AUTOSAR XML (schema 00049)
# Copyright (c) 2018 Vector Informatik GmbH.
standard types defined: boolean, uint16, uint32, uint8
package /VehicleProject
  system System
package /Diagnostics
  diagnostic contribution set DiagnosticContributionSet: ecu-instance=[MyECU, OtherECU, Tester], service-tables=[DS_MyECU, DS_OtherECU, DS_Tester]
  diagnostic service table DS_MyECU: diagnostic-connections=[DC_0xE001_oMyECU_oCAN, DC_0xE002_oMyECU_oCAN, DC_0xE004_oMyECU_oCAN], ecu-instance=MyECU
  diagnostic service table DS_OtherECU: diagnostic-connections=DC_0xE003_oOtherECU_oCAN, ecu-instance=OtherECU
  diagnostic service table DS_Tester: diagnostic-connections=[DC_0xE001_oMyECU_oCAN, DC_0xE002_oMyECU_oCAN, DC_0xE003_oOtherECU_oCAN, DC_0xE004_oMyECU_oCAN], ecu-instance=Tester
  4 x diagnostic connection, all with functional-request=msg_diag_RequestGlobal_oTN_0x00E0_Tester:
    DC_0xE001_oMyECU_oCAN: periodic-response-uudt=PT_msg_diag_Uudt_Response_MyECU, physical-request=msg_diag_Request_MyECU_oTN_0x0001_MyECU, response=msg_diag_Response_MyECU_oTN_0x0001_MyECU
    DC_0xE002_oMyECU_oCAN: physical-request=msg_diag_Request_MyECU_Slave3_oTN_0x0002_MyECU, response=msg_diag_Response_MyECU_Slave3_oTN_0x0002_MyECU
    DC_0xE003_oOtherECU_oCAN: periodic-response-uudt=PT_msg_diag_Uudt_Response_OtherECU, physical-request=msg_diag_Request_OtherECU_oTN_0x0003_OtherECU, response=msg_diag_Response_OtherECU_oTN_0x0003_OtherECU
    DC_0xE004_oMyECU_oCAN: physical-request=msg_diag_Request_MyECU_Slave1_oTN_0x0004_MyECU, response=msg_diag_Response_MyECU_Slave1_oTN_0x0004_MyECU
package /NM
  nm config NmConfig: can-nm-cluster-coupling=coupled-cluster=CAN
    can nm cluster CAN: communication-cluster=CAN, nm-channel-id=0, nm-cbv-position=0, nm-msg-cycle-time=0.1, nm-network-timeout=1, nm-nid-position=1, nm-repeat-message-time=0.4, nm-wait-bus-sleep-time=0.75
      can nm node MyECU: controller=MyECU/CT_CAN, nm-if-ecu=MyECU_CAN, nm-node-id=0, rx-nm-pdu=[msg_nm_OtherECU_oCAN, msg_nm_RearECU_oCAN], tx-nm-pdu=msg_nm_MyECU_oCAN, nm-msg-cycle-offset=0, nm-msg-reduced-time=0.05, nm-range-config={lower-can-id=1024, upper-can-id=1087}
      can nm node OtherECU: controller=OtherECU/CT_CAN, nm-if-ecu=OtherECU_CAN, nm-node-id=0, rx-nm-pdu=[msg_nm_MyECU_oCAN, msg_nm_RearECU_oCAN], tx-nm-pdu=msg_nm_OtherECU_oCAN, nm-msg-cycle-offset=0, nm-msg-reduced-time=0.05, nm-range-config={lower-can-id=1024, upper-can-id=1087}
      can nm node RearECU: controller=RearECU/CT_CAN, nm-if-ecu=RearECU_CAN, nm-node-id=1, rx-nm-pdu=[msg_nm_MyECU_oCAN, msg_nm_OtherECU_oCAN], tx-nm-pdu=msg_nm_RearECU_oCAN, nm-msg-cycle-offset=0, nm-msg-reduced-time=0.05, nm-range-config={lower-can-id=1024, upper-can-id=1087}
    nm-if-ecus:
      nm ecu MyECU_CAN: ecu-instance=MyECU, nm-node-id-enabled=true, nm-user-data-enabled=true
      nm ecu OtherECU_CAN: ecu-instance=OtherECU, nm-node-id-enabled=true, nm-user-data-enabled=true
      nm ecu RearECU_CAN: ecu-instance=RearECU, nm-node-id-enabled=true, nm-user-data-enabled=true
package /TP
  can tp config CAN: communication-cluster=CAN
    6 x can tp address:
      TA_0x0000: tp-address=0
      TA_0x0001: tp-address=1
      TA_0x0002: tp-address=2
      TA_0x0003: tp-address=3
      TA_0x0004: tp-address=4
      TA_0x00E0: tp-address=224
    can tp channel TPCH: channel-id=0, channel-mode=FULL-DUPLEX-MODE
    can-tp-connection addressing-format=STANDARD, can-tp-channel=TPCH, data-pdu=msg_diag_RequestGlobal_Tp_oCAN, multicast=TA_0x0000, receiver=[TN_MyECU, TN_OtherECU], ta-type=FUNCTIONAL, tp-sdu=msg_diag_RequestGlobal_oCAN, transmitter=TN_0x00E0_Tester:
      ident msg_diag_RequestGlobal_oTN_0x00E0_Tester
    can-tp-connection addressing-format=STANDARD, can-tp-channel=TPCH, data-pdu=msg_diag_Request_MyECU_Tp_oCAN, flow-control-pdu=msg_diag_Response_MyECU_Tp_oCAN, receiver=TN_0x0001_MyECU, ta-type=PHYSICAL, tp-sdu=msg_diag_Request_MyECU_oCAN, transmitter=TN_0x00E0_Tester:
      ident msg_diag_Request_MyECU_oTN_0x0001_MyECU
    can-tp-connection addressing-format=STANDARD, can-tp-channel=TPCH, data-pdu=msg_diag_Request_MyECU_Slave1_Tp_oCAN, flow-control-pdu=msg_diag_Response_MyECU_Slave1_Tp_oCAN, receiver=TN_0x0004_MyECU, ta-type=PHYSICAL, tp-sdu=msg_diag_Request_MyECU_Slave1_oCAN, transmitter=TN_0x00E0_Tester:
      ident msg_diag_Request_MyECU_Slave1_oTN_0x0004_MyECU
    can-tp-connection addressing-format=STANDARD, can-tp-channel=TPCH, data-pdu=msg_diag_Request_MyECU_Slave3_Tp_oCAN, flow-control-pdu=msg_diag_Response_MyECU_Slave3_Tp_oCAN, receiver=TN_0x0002_MyECU, ta-type=PHYSICAL, tp-sdu=msg_diag_Request_MyECU_Slave3_oCAN, transmitter=TN_0x00E0_Tester:
      ident msg_diag_Request_MyECU_Slave3_oTN_0x0002_MyECU
    can-tp-connection addressing-format=STANDARD, can-tp-channel=TPCH, data-pdu=msg_diag_Request_OtherECU_Tp_oCAN, flow-control-pdu=msg_diag_Response_OtherECU_Tp_oCAN, receiver=TN_0x0003_OtherECU, ta-type=PHYSICAL, tp-sdu=msg_diag_Request_OtherECU_oCAN, transmitter=TN_0x00E0_Tester:
      ident msg_diag_Request_OtherECU_oTN_0x0003_OtherECU
    can-tp-connection addressing-format=STANDARD, can-tp-channel=TPCH, data-pdu=msg_diag_Response_MyECU_Tp_oCAN, flow-control-pdu=msg_diag_Request_MyECU_Tp_oCAN, receiver=TN_0x00E0_Tester, ta-type=PHYSICAL, tp-sdu=msg_diag_Response_MyECU_oCAN, transmitter=TN_0x0001_MyECU:
      ident msg_diag_Response_MyECU_oTN_0x0001_MyECU
    can-tp-connection addressing-format=STANDARD, can-tp-channel=TPCH, data-pdu=msg_diag_Response_MyECU_Slave1_Tp_oCAN, flow-control-pdu=msg_diag_Request_MyECU_Slave1_Tp_oCAN, receiver=TN_0x00E0_Tester, ta-type=PHYSICAL, tp-sdu=msg_diag_Response_MyECU_Slave1_oCAN, transmitter=TN_0x0004_MyECU:
      ident msg_diag_Response_MyECU_Slave1_oTN_0x0004_MyECU
    can-tp-connection addressing-format=STANDARD, can-tp-channel=TPCH, data-pdu=msg_diag_Response_MyECU_Slave3_Tp_oCAN, flow-control-pdu=msg_diag_Request_MyECU_Slave3_Tp_oCAN, receiver=TN_0x00E0_Tester, ta-type=PHYSICAL, tp-sdu=msg_diag_Response_MyECU_Slave3_oCAN, transmitter=TN_0x0002_MyECU:
      ident msg_diag_Response_MyECU_Slave3_oTN_0x0002_MyECU
    can-tp-connection addressing-format=STANDARD, can-tp-channel=TPCH, data-pdu=msg_diag_Response_OtherECU_Tp_oCAN, flow-control-pdu=msg_diag_Request_OtherECU_Tp_oCAN, receiver=TN_0x00E0_Tester, ta-type=PHYSICAL, tp-sdu=msg_diag_Response_OtherECU_oCAN, transmitter=TN_0x0003_OtherECU:
      ident msg_diag_Response_OtherECU_oTN_0x0003_OtherECU
    tp-ecus:
      cycle-time-main-function=0.005, ecu-instance=MyECU
      cycle-time-main-function=0.005, ecu-instance=OtherECU
      cycle-time-main-function=0.005, ecu-instance=Tester
    7 x can tp node:
      TN_0x0001_MyECU: connector=MyECU/CN_CAN, tp-address=TA_0x0001
      TN_0x0002_MyECU: connector=MyECU/CN_CAN, tp-address=TA_0x0002
      TN_0x0003_OtherECU: connector=OtherECU/CN_CAN, tp-address=TA_0x0003
      TN_0x0004_MyECU: connector=MyECU/CN_CAN, tp-address=TA_0x0004
      TN_0x00E0_Tester: connector=Tester/CN_CAN, tp-address=TA_0x00E0
      TN_MyECU: connector=MyECU/CN_CAN
      TN_OtherECU: connector=OtherECU/CN_CAN
package /Cluster
  can cluster CAN: baudrate=500000, protocol-name=CAN, can-fd-baudrate=500000  # CAN_SecOC_FD_Mode2
    can physical channel CHNL: comm-connectors=[MyECU/CN_CAN, OtherECU/CN_CAN, RearECU/CN_CAN, Tester/CN_CAN]
      frame GlobalTimeMaster_oCAN: id 0x380, from RearECU, to MyECU OtherECU, frame-length=8, can-addressing-mode=STANDARD, can-frame-rx-behavior=ANY, can-frame-tx-behavior=CAN-20
        user defined pdu GlobalTimeMaster_oCAN: length=8
      frame msg_diag_Request_MyECU_oCAN: id 0x610, from Tester, to MyECU, frame-length=8, can-addressing-mode=STANDARD, can-frame-rx-behavior=CAN-20, can-frame-tx-behavior=CAN-20
        n pdu msg_diag_Request_MyECU_Tp_oCAN: length=8
      frame msg_diag_Request_MyECU_Slave1_oCAN: id 0x615, from Tester, to MyECU, frame-length=8, can-addressing-mode=STANDARD, can-frame-rx-behavior=CAN-20, can-frame-tx-behavior=CAN-20
        n pdu msg_diag_Request_MyECU_Slave1_Tp_oCAN: length=8
      frame msg_diag_Request_MyECU_Slave3_oCAN: id 0x611, from Tester, to MyECU, frame-length=8, can-addressing-mode=STANDARD, can-frame-rx-behavior=CAN-20, can-frame-tx-behavior=CAN-20
        n pdu msg_diag_Request_MyECU_Slave3_Tp_oCAN: length=8
      frame msg_diag_Request_OtherECU_oCAN: id 0x620, from Tester, to OtherECU, frame-length=8, can-addressing-mode=STANDARD, can-frame-rx-behavior=CAN-20, can-frame-tx-behavior=CAN-20
        n pdu msg_diag_Request_OtherECU_Tp_oCAN: length=8
      frame msg_diag_RequestGlobal_oCAN: id 0x614, from Tester, to MyECU OtherECU, frame-length=8, can-addressing-mode=STANDARD, can-frame-rx-behavior=CAN-20, can-frame-tx-behavior=CAN-20
        n pdu msg_diag_RequestGlobal_Tp_oCAN: length=8
      frame msg_diag_Response_MyECU_oCAN: id 0x612, from MyECU, to Tester, frame-length=8, can-addressing-mode=STANDARD, can-frame-rx-behavior=CAN-20, can-frame-tx-behavior=CAN-20
        n pdu msg_diag_Response_MyECU_Tp_oCAN: length=8
      frame msg_diag_Response_MyECU_Slave1_oCAN: id 0x618, from MyECU, to Tester, frame-length=8, can-addressing-mode=STANDARD, can-frame-rx-behavior=CAN-20, can-frame-tx-behavior=CAN-20
        n pdu msg_diag_Response_MyECU_Slave1_Tp_oCAN: length=8
      frame msg_diag_Response_MyECU_Slave3_oCAN: id 0x613, from MyECU, to Tester, frame-length=8, can-addressing-mode=STANDARD, can-frame-rx-behavior=CAN-20, can-frame-tx-behavior=CAN-20
        n pdu msg_diag_Response_MyECU_Slave3_Tp_oCAN: length=8
      frame msg_diag_Response_OtherECU_oCAN: id 0x622, from OtherECU, to Tester, frame-length=8, can-addressing-mode=STANDARD, can-frame-rx-behavior=CAN-20, can-frame-tx-behavior=CAN-20
        n pdu msg_diag_Response_OtherECU_Tp_oCAN: length=8
      frame msg_diag_Uudt_Response_MyECU_oCAN: id 0x616, from MyECU, to Tester, frame-length=8, can-addressing-mode=STANDARD, can-frame-rx-behavior=CAN-20, can-frame-tx-behavior=CAN-20
        dcm i pdu msg_diag_Uudt_Response_MyECU_oCAN: length=8, diag-pdu-type=DIAG-RESPONSE
      frame msg_diag_Uudt_Response_OtherECU_oCAN: id 0x626, from OtherECU, to Tester, frame-length=8, can-addressing-mode=STANDARD, can-frame-rx-behavior=CAN-20, can-frame-tx-behavior=CAN-20
        dcm i pdu msg_diag_Uudt_Response_OtherECU_oCAN: length=8, diag-pdu-type=DIAG-RESPONSE
      frame msg_nm_MyECU_oCAN: id 0x400, from MyECU, to OtherECU RearECU, frame-length=8, can-addressing-mode=STANDARD, can-frame-rx-behavior=ANY, can-frame-tx-behavior=CAN-20
        nm pdu msg_nm_MyECU_oCAN: length=8, unused-bit-pattern=0
          signal NmUd_MyECU_16bit_omsg_nm_MyECU_oCAN: start 16, 16 bit, little-endian, i-signal-type=PRIMITIVE, init-value=0, base-type=uint16, compu {identical}, range raw 0..65535, transfer-property=PENDING
          signal NmUd_MyECU_32bit_omsg_nm_MyECU_oCAN: start 32, 32 bit, little-endian, i-signal-type=PRIMITIVE, init-value=0, base-type=uint32, compu {identical}, range raw 0..4294967295, transfer-property=PENDING
      frame msg_nm_OtherECU_oCAN: id 0x402, from OtherECU, to MyECU RearECU, frame-length=8, can-addressing-mode=STANDARD, can-frame-rx-behavior=ANY, can-frame-tx-behavior=CAN-20
        nm pdu msg_nm_OtherECU_oCAN: length=8, unused-bit-pattern=0
          signal NmUd_OtherECU_16bit_omsg_nm_OtherECU_oCAN: start 16, 16 bit, little-endian, i-signal-type=PRIMITIVE, init-value=0, base-type=uint16, compu {identical}, range raw 0..65535, transfer-property=PENDING
          signal NmUd_OtherECU_32bit_omsg_nm_OtherECU_oCAN: start 32, 32 bit, little-endian, i-signal-type=PRIMITIVE, init-value=0, base-type=uint32, compu {identical}, range raw 0..4294967295, transfer-property=PENDING
      frame msg_nm_RearECU_oCAN: id 0x401, from RearECU, to MyECU OtherECU, frame-length=8, can-addressing-mode=STANDARD, can-frame-rx-behavior=ANY, can-frame-tx-behavior=CAN-20
        nm pdu msg_nm_RearECU_oCAN: length=8, unused-bit-pattern=0
          signal NmUd_RearECU_16bit_omsg_nm_RearECU_oCAN: start 16, 16 bit, little-endian, i-signal-type=PRIMITIVE, init-value=0, base-type=uint16, compu {identical}, range raw 0..65535, transfer-property=PENDING
          signal NmUd_RearECU_32bit_omsg_nm_RearECU_oCAN: start 32, 32 bit, little-endian, i-signal-type=PRIMITIVE, init-value=0, base-type=uint32, compu {identical}, range raw 0..4294967295, transfer-property=PENDING
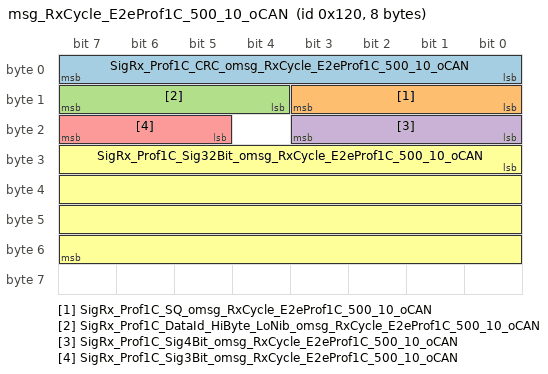
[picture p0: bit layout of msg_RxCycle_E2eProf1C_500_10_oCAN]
      frame msg_RxCycle_E2eProf1C_500_10_oCAN: id 0x120, from RearECU, to MyECU, frame-length=8, can-addressing-mode=STANDARD, can-frame-rx-behavior=ANY, can-frame-tx-behavior=CAN-FD
        pdu msg_RxCycle_E2eProf1C_500_10_oCAN: length=8, minimum-delay=0, transmission-mode-false-timing=cyclic-timing={time-offset=0.01, time-period=0.5}, transmission-mode-true-timing=cyclic-timing={time-offset=0.01, time-period=0.5}, unused-bit-pattern=0
          signal SigRx_Prof1C_CRC_omsg_RxCycle_E2eProf1C_500_10_oCAN: start 0, 8 bit, little-endian, i-signal-type=PRIMITIVE, init-value=0, base-type=uint8, compu {identical}, range raw 0..255, transfer-property=PENDING, to MyECU
          signal SigRx_Prof1C_SQ_omsg_RxCycle_E2eProf1C_500_10_oCAN: start 8, 4 bit, little-endian, i-signal-type=PRIMITIVE, init-value=0, base-type=uint8, compu {identical}, range raw 0..15, transfer-property=PENDING, to MyECU
          signal SigRx_Prof1C_DataId_HiByte_LoNib_omsg_RxCycle_E2eProf1C_500_10_oCAN: start 12, 4 bit, little-endian, i-signal-type=PRIMITIVE, init-value=0, base-type=uint8, compu {identical}, range raw 0..15, transfer-property=PENDING, to MyECU
          signal SigRx_Prof1C_Sig4Bit_omsg_RxCycle_E2eProf1C_500_10_oCAN: start 16, 4 bit, little-endian, i-signal-type=PRIMITIVE, init-value=0, base-type=uint8, compu {identical}, range raw 0..15, transfer-property=PENDING, to MyECU
          signal SigRx_Prof1C_Sig3Bit_omsg_RxCycle_E2eProf1C_500_10_oCAN: start 21, 3 bit, little-endian, i-signal-type=PRIMITIVE, init-value=0, base-type=uint8, compu {identical}, range raw 0..7, transfer-property=PENDING, to MyECU
          signal SigRx_Prof1C_Sig32Bit_omsg_RxCycle_E2eProf1C_500_10_oCAN: start 24, 32 bit, little-endian, i-signal-type=PRIMITIVE, init-value=0, base-type=uint32, compu {identical}, range raw 0..4294967295, transfer-property=PENDING, to MyECU
          mapping SG_RgRx_Prof1C_RxCycle: i-signal-group=SG_RgRx_Prof1C_RxCycle_omsg_RxCycle_E2eProf1C_500_10_oCAN, transfer-property=PENDING
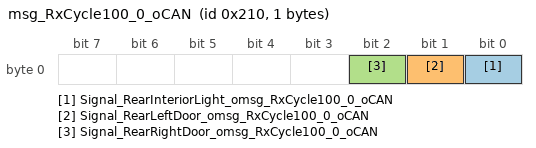
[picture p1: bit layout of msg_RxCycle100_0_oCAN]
      frame msg_RxCycle100_0_oCAN: id 0x210, from RearECU, to MyECU, frame-length=1, can-addressing-mode=STANDARD, can-frame-rx-behavior=ANY, can-frame-tx-behavior=CAN-FD
        pdu msg_RxCycle100_0_oCAN: length=1, minimum-delay=0, transmission-mode-false-timing=cyclic-timing={time-offset=0, time-period=0.1}, transmission-mode-true-timing=cyclic-timing={time-offset=0, time-period=0.1}, unused-bit-pattern=0
          signal Signal_RearInteriorLight_omsg_RxCycle100_0_oCAN: start 0, 1 bit, little-endian, i-signal-type=PRIMITIVE, init-value=0, base-type=boolean, compu {identical}, range raw 0..1, transfer-property=PENDING, to MyECU
          signal Signal_RearLeftDoor_omsg_RxCycle100_0_oCAN: start 1, 1 bit, little-endian, i-signal-type=PRIMITIVE, init-value=0, base-type=boolean, compu {identical}, range raw 0..1, transfer-property=PENDING, to MyECU
          signal Signal_RearRightDoor_omsg_RxCycle100_0_oCAN: start 2, 1 bit, little-endian, i-signal-type=PRIMITIVE, init-value=0, base-type=boolean, compu {identical}, range raw 0..1, transfer-property=PENDING, to MyECU
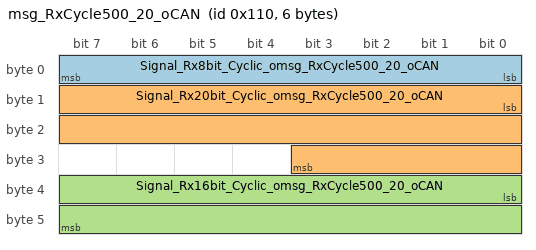
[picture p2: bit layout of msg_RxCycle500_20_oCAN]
      frame msg_RxCycle500_20_oCAN: id 0x110, from RearECU, to MyECU, frame-length=6, can-addressing-mode=STANDARD, can-frame-rx-behavior=ANY, can-frame-tx-behavior=CAN-FD
        pdu msg_RxCycle500_20_oCAN: length=6, minimum-delay=0, transmission-mode-false-timing=cyclic-timing={time-offset=0.02, time-period=0.5}, transmission-mode-true-timing=cyclic-timing={time-offset=0.02, time-period=0.5}, unused-bit-pattern=0
          signal Signal_Rx8bit_Cyclic_omsg_RxCycle500_20_oCAN: start 0, 8 bit, little-endian, i-signal-type=PRIMITIVE, init-value=15, base-type=uint8, compu {identical}, range raw 0..255, transfer-property=PENDING, to MyECU
          signal Signal_Rx20bit_Cyclic_omsg_RxCycle500_20_oCAN: start 8, 20 bit, little-endian, i-signal-type=PRIMITIVE, init-value=1, base-type=uint32, compu {identical}, range raw 0..1048575, transfer-property=PENDING, to MyECU
          signal Signal_Rx16bit_Cyclic_omsg_RxCycle500_20_oCAN: start 32, 16 bit, little-endian, i-signal-type=PRIMITIVE, init-value=32768, base-type=uint16, compu {identical}, range raw 0..65535, transfer-property=PENDING, to MyECU
      frame msg_RxEvent_20_oCAN: id 0x310, from RearECU, to MyECU, frame-length=4, can-addressing-mode=STANDARD, can-frame-rx-behavior=ANY, can-frame-tx-behavior=CAN-FD
        pdu msg_RxEvent_20_oCAN: length=4, minimum-delay=0, transmission-mode-false-timing=event-controlled-timing={number-of-repetitions=0, repetition-period=0}, transmission-mode-true-timing=event-controlled-timing={number-of-repetitions=0, repetition-period=0}, unused-bit-pattern=0
          signal Signal_Rx11bit_OnWrite_omsg_RxEvent_20_oCAN: start 0, 11 bit, little-endian, i-signal-type=PRIMITIVE, init-value=50, base-type=uint16, compu {identical}, range raw 0..2047, transfer-property=TRIGGERED-WITHOUT-REPETITION, to MyECU
          signal Signal_Rx15bit_OnWrite_omsg_RxEvent_20_oCAN: start 12, 15 bit, little-endian, i-signal-type=PRIMITIVE, init-value=25, base-type=uint16, compu {identical}, range raw 0..32767, transfer-property=TRIGGERED-WITHOUT-REPETITION, to MyECU
      frame msg_SecOC_MyECU_Rx_oCAN: id 0x528, from RearECU, to MyECU, frame-length=8, can-addressing-mode=STANDARD, can-frame-rx-behavior=ANY, can-frame-tx-behavior=CAN-20
        secured i pdu msg_SecOC_MyECU_Rx_Sc_oCAN: length=8, authentication-props=Authmsg_SecOC_MyECU_Rx_Sc_oCAN, freshness-props=Freshnessmsg_SecOC_MyECU_Rx_Sc_oCAN, payload=PT_msg_SecOC_MyECU_Rx, secure-communication-props={auth-info-tx-length=32, data-id=11, freshness-value-length=32, freshness-value-tx-length=16}
      frame msg_SecOC_MyECU_Tx_oCAN: id 0x520, from MyECU, to RearECU, frame-length=8, can-addressing-mode=STANDARD, can-frame-rx-behavior=ANY, can-frame-tx-behavior=CAN-20
        secured i pdu msg_SecOC_MyECU_Tx_Sc_oCAN: length=8, authentication-props=Authmsg_SecOC_MyECU_Tx_Sc_oCAN, freshness-props=Freshnessmsg_SecOC_MyECU_Tx_Sc_oCAN, payload=PT_msg_SecOC_MyECU_Tx, secure-communication-props={auth-info-tx-length=32, data-id=10, freshness-value-length=32, freshness-value-tx-length=16}
      frame msg_SecOC_OtherECU_Rx_oCAN: id 0x538, from RearECU, to OtherECU, frame-length=8, can-addressing-mode=STANDARD, can-frame-rx-behavior=ANY, can-frame-tx-behavior=CAN-20
        secured i pdu msg_SecOC_OtherECU_Rx_Sc_oCAN: length=8, authentication-props=Authmsg_SecOC_OtherECU_Rx_Sc_oCAN, freshness-props=Freshnessmsg_SecOC_OtherECU_Rx_Sc_oCAN, payload=PT_msg_SecOC_OtherECU_Rx, secure-communication-props={auth-info-tx-length=32, data-id=21, freshness-value-length=32, freshness-value-tx-length=16}
      frame msg_SecOC_OtherECU_Tx_oCAN: id 0x530, from OtherECU, to RearECU, frame-length=8, can-addressing-mode=STANDARD, can-frame-rx-behavior=ANY, can-frame-tx-behavior=CAN-20
        secured i pdu msg_SecOC_OtherECU_Tx_Sc_oCAN: length=8, authentication-props=Authmsg_SecOC_OtherECU_Tx_Sc_oCAN, freshness-props=Freshnessmsg_SecOC_OtherECU_Tx_Sc_oCAN, payload=PT_msg_SecOC_OtherECU_Tx, secure-communication-props={auth-info-tx-length=32, data-id=20, freshness-value-length=32, freshness-value-tx-length=16}
      frame msg_StartAppl_Rx_MyECU_oCAN: id 0x501, from RearECU, to MyECU, frame-length=64, can-addressing-mode=STANDARD, can-frame-rx-behavior=ANY, can-frame-tx-behavior=CAN-FD
        pdu msg_StartAppl_Rx_MyECU_oCAN: length=64, minimum-delay=0, transmission-mode-false-timing=cyclic-timing={time-offset=0, time-period=0.05}, transmission-mode-true-timing=cyclic-timing={time-offset=0, time-period=0.05}, unused-bit-pattern=0
          signal Signal_StartAppl_RxCtrl_MyECU_omsg_StartAppl_Rx_MyECU_oCAN: start 0, 8 bit, little-endian, i-signal-type=PRIMITIVE, init-value=0, base-type=uint8, compu {identical}, range raw 0..255, transfer-property=PENDING, to MyECU
          signal Signal_StartAppl_RxData_MyECU_omsg_StartAppl_Rx_MyECU_oCAN: start 504, 8 bit, little-endian, i-signal-type=PRIMITIVE, init-value=0, base-type=uint8, compu {identical}, range raw 0..255, transfer-property=PENDING, to MyECU
      frame msg_StartAppl_Rx_OtherECU_oCAN: id 0x511, from RearECU, to OtherECU, frame-length=64, can-addressing-mode=STANDARD, can-frame-rx-behavior=ANY, can-frame-tx-behavior=CAN-FD
        pdu msg_StartAppl_Rx_OtherECU_oCAN: length=64, minimum-delay=0, transmission-mode-false-timing=cyclic-timing={time-offset=0, time-period=0.05}, transmission-mode-true-timing=cyclic-timing={time-offset=0, time-period=0.05}, unused-bit-pattern=0
          signal Signal_StartAppl_RxCtrl_OtherECU_omsg_StartAppl_Rx_OtherECU_oCAN: start 0, 8 bit, little-endian, i-signal-type=PRIMITIVE, init-value=0, base-type=uint8, compu {identical}, range raw 0..255, transfer-property=PENDING, to OtherECU
          signal Signal_StartAppl_RxData_OtherECU_omsg_StartAppl_Rx_OtherECU_oCAN: start 8, 8 bit, little-endian, i-signal-type=PRIMITIVE, init-value=0, base-type=uint8, compu {identical}, range raw 0..255, transfer-property=PENDING, to OtherECU
      frame msg_StartAppl_Tx_MyECU_oCAN: id 0x500, from MyECU, to RearECU, frame-length=64, can-addressing-mode=STANDARD, can-frame-rx-behavior=ANY, can-frame-tx-behavior=CAN-FD
        pdu msg_StartAppl_Tx_MyECU_oCAN: length=64, minimum-delay=0, transmission-mode-false-timing=cyclic-timing={time-offset=0, time-period=0.05}, transmission-mode-true-timing=cyclic-timing={time-offset=0, time-period=0.05}, unused-bit-pattern=0
          signal Signal_StartAppl_TxCtrl_MyECU_omsg_StartAppl_Tx_MyECU_oCAN: start 0, 8 bit, little-endian, i-signal-type=PRIMITIVE, init-value=0, base-type=uint8, compu {identical}, range raw 0..255, transfer-property=PENDING, to RearECU
          signal Signal_StartAppl_TxData_MyECU_omsg_StartAppl_Tx_MyECU_oCAN: start 504, 8 bit, little-endian, i-signal-type=PRIMITIVE, init-value=0, base-type=uint8, compu {identical}, range raw 0..255, transfer-property=PENDING, to RearECU
      frame msg_StartAppl_Tx_OtherECU_oCAN: id 0x510, from OtherECU, to RearECU, frame-length=64, can-addressing-mode=STANDARD, can-frame-rx-behavior=ANY, can-frame-tx-behavior=CAN-FD
        pdu msg_StartAppl_Tx_OtherECU_oCAN: length=64, minimum-delay=0, transmission-mode-false-timing=cyclic-timing={time-offset=0, time-period=0.05}, transmission-mode-true-timing=cyclic-timing={time-offset=0, time-period=0.05}, unused-bit-pattern=0
          signal Signal_StartAppl_TxCtrl_OtherECU_omsg_StartAppl_Tx_OtherECU_oCAN: start 0, 8 bit, little-endian, i-signal-type=PRIMITIVE, init-value=0, base-type=uint8, compu {identical}, range raw 0..255, transfer-property=PENDING, to RearECU
          signal Signal_StartAppl_TxData_OtherECU_omsg_StartAppl_Tx_OtherECU_oCAN: start 8, 8 bit, little-endian, i-signal-type=PRIMITIVE, init-value=0, base-type=uint8, compu {identical}, range raw 0..255, transfer-property=PENDING, to RearECU
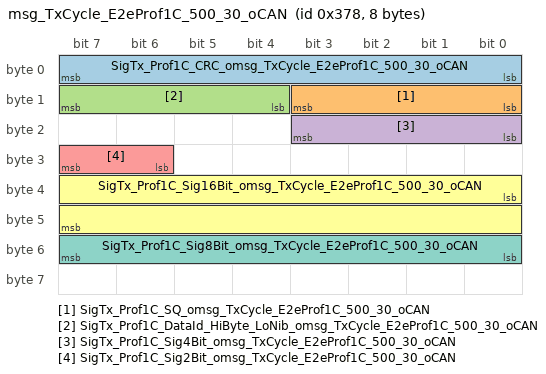
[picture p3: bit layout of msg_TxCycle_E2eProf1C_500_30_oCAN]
      frame msg_TxCycle_E2eProf1C_500_30_oCAN: id 0x378, from MyECU, to RearECU, frame-length=8, can-addressing-mode=STANDARD, can-frame-rx-behavior=ANY, can-frame-tx-behavior=CAN-FD
        pdu msg_TxCycle_E2eProf1C_500_30_oCAN: length=8, minimum-delay=0, transmission-mode-false-timing=cyclic-timing={time-offset=0.03, time-period=0.5}, transmission-mode-true-timing=cyclic-timing={time-offset=0.03, time-period=0.5}, unused-bit-pattern=0
          signal SigTx_Prof1C_CRC_omsg_TxCycle_E2eProf1C_500_30_oCAN: start 0, 8 bit, little-endian, i-signal-type=PRIMITIVE, init-value=0, base-type=uint8, compu {identical}, range raw 0..255, transfer-property=PENDING, to RearECU
          signal SigTx_Prof1C_SQ_omsg_TxCycle_E2eProf1C_500_30_oCAN: start 8, 4 bit, little-endian, i-signal-type=PRIMITIVE, init-value=0, base-type=uint8, compu {identical}, range raw 0..15, transfer-property=PENDING, to RearECU
          signal SigTx_Prof1C_DataId_HiByte_LoNib_omsg_TxCycle_E2eProf1C_500_30_oCAN: start 12, 4 bit, little-endian, i-signal-type=PRIMITIVE, init-value=0, base-type=uint8, compu {identical}, range raw 0..15, transfer-property=PENDING, to RearECU
          signal SigTx_Prof1C_Sig4Bit_omsg_TxCycle_E2eProf1C_500_30_oCAN: start 16, 4 bit, little-endian, i-signal-type=PRIMITIVE, init-value=0, base-type=uint8, compu {identical}, range raw 0..15, transfer-property=PENDING, to RearECU
          signal SigTx_Prof1C_Sig2Bit_omsg_TxCycle_E2eProf1C_500_30_oCAN: start 30, 2 bit, little-endian, i-signal-type=PRIMITIVE, init-value=0, base-type=uint8, compu {identical}, range raw 0..3, transfer-property=PENDING, to RearECU
          signal SigTx_Prof1C_Sig16Bit_omsg_TxCycle_E2eProf1C_500_30_oCAN: start 32, 16 bit, little-endian, i-signal-type=PRIMITIVE, init-value=0, base-type=uint16, compu {identical}, range raw 0..65535, transfer-property=PENDING, to RearECU
          signal SigTx_Prof1C_Sig8Bit_omsg_TxCycle_E2eProf1C_500_30_oCAN: start 48, 8 bit, little-endian, i-signal-type=PRIMITIVE, init-value=0, base-type=uint8, compu {identical}, range raw 0..255, transfer-property=PENDING, to RearECU
          mapping SG_SgTx_Prof1C_TxCycle: i-signal-group=SG_SgTx_Prof1C_TxCycle_omsg_TxCycle_E2eProf1C_500_30_oCAN, transfer-property=PENDING
      frame msg_TxCycle10_0_oCAN: id 0x268, from MyECU, to RearECU, frame-length=7, can-addressing-mode=STANDARD, can-frame-rx-behavior=ANY, can-frame-tx-behavior=CAN-FD
        pdu msg_TxCycle10_0_oCAN: length=7, minimum-delay=0, transmission-mode-false-timing=cyclic-timing={time-offset=0, time-period=0.01}, transmission-mode-true-timing=cyclic-timing={time-offset=0, time-period=0.01}, unused-bit-pattern=0
          signal Signal_Tx32bit_Cyclic_omsg_TxCycle10_0_oCAN: start 0, 32 bit, little-endian, i-signal-type=PRIMITIVE, init-value=0, base-type=uint32, compu {identical}, range raw 0..4294967295, transfer-property=PENDING, to RearECU
          signal Signal_Tx24bit_Cyclic_omsg_TxCycle10_0_oCAN: start 32, 24 bit, little-endian, i-signal-type=PRIMITIVE, init-value=0, base-type=uint32, compu {identical}, range raw 0..16777215, transfer-property=PENDING, to RearECU
      frame msg_TxCycle1000_10_oCAN: id 0x368, from MyECU, to RearECU, frame-length=2, can-addressing-mode=STANDARD, can-frame-rx-behavior=ANY, can-frame-tx-behavior=CAN-FD
        pdu msg_TxCycle1000_10_oCAN: length=2, minimum-delay=0, transmission-mode-false-timing=cyclic-timing={time-offset=0.01, time-period=1}, transmission-mode-true-timing=cyclic-timing={time-offset=0.01, time-period=1}, unused-bit-pattern=0
          signal Signal_Tx10bit_Cyclic_omsg_TxCycle1000_10_oCAN: start 0, 10 bit, little-endian, i-signal-type=PRIMITIVE, init-value=0, base-type=uint16, compu {identical}, range raw 0..1023, transfer-property=PENDING, to RearECU
          signal Signal_Tx4bit_Cyclic_omsg_TxCycle1000_10_oCAN: start 10, 4 bit, little-endian, i-signal-type=PRIMITIVE, init-value=0, base-type=uint8, compu {identical}, range raw 0..15, transfer-property=PENDING, to RearECU
      frame msg_TxEvent_10_oCAN: id 0x168, from MyECU, to RearECU, frame-length=7, can-addressing-mode=STANDARD, can-frame-rx-behavior=ANY, can-frame-tx-behavior=CAN-FD
        pdu msg_TxEvent_10_oCAN: length=7, minimum-delay=0, transmission-mode-false-timing=event-controlled-timing={number-of-repetitions=0, repetition-period=0}, transmission-mode-true-timing=event-controlled-timing={number-of-repetitions=0, repetition-period=0}, unused-bit-pattern=0
          signal Signal_Tx32bit_OnWrite_omsg_TxEvent_10_oCAN: start 0, 32 bit, little-endian, i-signal-type=PRIMITIVE, init-value=31, base-type=uint32, compu {identical}, range raw 0..4294967295, transfer-property=TRIGGERED-WITHOUT-REPETITION, to RearECU
          signal Signal_Tx24bit_OnWrite_omsg_TxEvent_10_oCAN: start 32, 24 bit, little-endian, i-signal-type=PRIMITIVE, init-value=63, base-type=uint32, compu {identical}, range raw 0..16777215, transfer-property=TRIGGERED-WITHOUT-REPETITION, to RearECU
      frame msg_XCP_Request_MyECU_oCAN: id 0x703, from Tester, to MyECU, frame-length=8, can-addressing-mode=STANDARD, can-frame-rx-behavior=ANY, can-frame-tx-behavior=CAN-20
        xcp pdu msg_XCP_Request_MyECU_oCAN: length=8
      frame msg_XCP_Request_OtherECU_oCAN: id 0x705, from Tester, to OtherECU, frame-length=8, can-addressing-mode=STANDARD, can-frame-rx-behavior=ANY, can-frame-tx-behavior=CAN-20
        xcp pdu msg_XCP_Request_OtherECU_oCAN: length=8
      frame msg_XCP_Response_MyECU_oCAN: id 0x704, from MyECU, to Tester, frame-length=8, can-addressing-mode=STANDARD, can-frame-rx-behavior=ANY, can-frame-tx-behavior=CAN-20
        xcp pdu msg_XCP_Response_MyECU_oCAN: length=8
      frame msg_XCP_Response_OtherECU_oCAN: id 0x706, from OtherECU, to Tester, frame-length=8, can-addressing-mode=STANDARD, can-frame-rx-behavior=ANY, can-frame-tx-behavior=CAN-20
        xcp pdu msg_XCP_Response_OtherECU_oCAN: length=8
      pdu triggering PT_msg_diag_Request_MyECU: pdu=msg_diag_Request_MyECU_oCAN, from Tester, to MyECU
      pdu triggering PT_msg_diag_Request_MyECU_Slave1: pdu=msg_diag_Request_MyECU_Slave1_oCAN, from Tester, to MyECU
      pdu triggering PT_msg_diag_Request_MyECU_Slave3: pdu=msg_diag_Request_MyECU_Slave3_oCAN, from Tester, to MyECU
      pdu triggering PT_msg_diag_Request_OtherECU: pdu=msg_diag_Request_OtherECU_oCAN, from Tester, to OtherECU
      pdu triggering PT_msg_diag_RequestGlobal: pdu=msg_diag_RequestGlobal_oCAN, from Tester, to MyECU OtherECU
      pdu triggering PT_msg_diag_Response_MyECU: pdu=msg_diag_Response_MyECU_oCAN, from MyECU, to Tester
      pdu triggering PT_msg_diag_Response_MyECU_Slave1: pdu=msg_diag_Response_MyECU_Slave1_oCAN, from MyECU, to Tester
      pdu triggering PT_msg_diag_Response_MyECU_Slave3: pdu=msg_diag_Response_MyECU_Slave3_oCAN, from MyECU, to Tester
      pdu triggering PT_msg_diag_Response_OtherECU: pdu=msg_diag_Response_OtherECU_oCAN, from OtherECU, to Tester
      pdu triggering PT_msg_SecOC_MyECU_Rx: pdu=msg_SecOC_MyECU_Rx_oCAN, from RearECU, to MyECU
      pdu triggering PT_msg_SecOC_MyECU_Tx: pdu=msg_SecOC_MyECU_Tx_oCAN, from MyECU, to RearECU
      pdu triggering PT_msg_SecOC_OtherECU_Rx: pdu=msg_SecOC_OtherECU_Rx_oCAN, from RearECU, to OtherECU
      pdu triggering PT_msg_SecOC_OtherECU_Tx: pdu=msg_SecOC_OtherECU_Tx_oCAN, from OtherECU, to RearECU
package /ECU
  4 x ecu instance:
    MyECU: associated-com-i-pdu-group=[MyECU_oCAN_Rx, MyECU_oCAN_Tx]
      can communication controller CT_CAN
      can communication connector CN_CAN: comm-controller=MyECU/CT_CAN
    OtherECU: associated-com-i-pdu-group=[OtherECU_oCAN_Rx, OtherECU_oCAN_Tx]
      can communication controller CT_CAN
      can communication connector CN_CAN: comm-controller=OtherECU/CT_CAN
    RearECU: associated-com-i-pdu-group=[RearECU_oCAN_Rx, RearECU_oCAN_Tx]
      can communication controller CT_CAN
      can communication connector CN_CAN: comm-controller=RearECU/CT_CAN
    Tester
      can communication controller CT_CAN
      can communication connector CN_CAN: comm-controller=Tester/CT_CAN
package /IPDUGroup
  6 x i signal i pdu group:
    MyECU_oCAN_Rx: communication-direction=IN
      i-signal-i-pdus:
        msg_RxCycle_E2eProf1C_500_10_oCAN
        msg_RxCycle100_0_oCAN
        msg_RxCycle500_20_oCAN
        msg_RxEvent_20_oCAN
        msg_SecOC_MyECU_Rx_oCAN
        msg_StartAppl_Rx_MyECU_oCAN
    MyECU_oCAN_Tx: communication-direction=OUT
      i-signal-i-pdus:
        msg_SecOC_MyECU_Tx_oCAN
        msg_StartAppl_Tx_MyECU_oCAN
        msg_TxCycle_E2eProf1C_500_30_oCAN
        msg_TxCycle10_0_oCAN
        msg_TxCycle1000_10_oCAN
        msg_TxEvent_10_oCAN
    OtherECU_oCAN_Rx: communication-direction=IN, i-signal-i-pdus=[msg_SecOC_OtherECU_Rx_oCAN, msg_StartAppl_Rx_OtherECU_oCAN]
    OtherECU_oCAN_Tx: communication-direction=OUT, i-signal-i-pdus=[msg_SecOC_OtherECU_Tx_oCAN, msg_StartAppl_Tx_OtherECU_oCAN]
    RearECU_oCAN_Rx: communication-direction=IN
      i-signal-i-pdus:
        msg_SecOC_MyECU_Tx_oCAN
        msg_SecOC_OtherECU_Tx_oCAN
        msg_StartAppl_Tx_MyECU_oCAN
        msg_StartAppl_Tx_OtherECU_oCAN
        msg_TxCycle_E2eProf1C_500_30_oCAN
        msg_TxCycle10_0_oCAN
        msg_TxCycle1000_10_oCAN
        msg_TxEvent_10_oCAN
    RearECU_oCAN_Tx: communication-direction=OUT
      i-signal-i-pdus:
        msg_RxCycle_E2eProf1C_500_10_oCAN
        msg_RxCycle100_0_oCAN
        msg_RxCycle500_20_oCAN
        msg_RxEvent_20_oCAN
        msg_SecOC_MyECU_Rx_oCAN
        msg_SecOC_OtherECU_Rx_oCAN
        msg_StartAppl_Rx_MyECU_oCAN
        msg_StartAppl_Rx_OtherECU_oCAN
package /PDU
  pdu msg_SecOC_MyECU_Rx_oCAN: length=2, minimum-delay=0, transmission-mode-false-timing=cyclic-timing={time-offset=0, time-period=0.1}, transmission-mode-true-timing=cyclic-timing={time-offset=0, time-period=0.1}, unused-bit-pattern=0
    signal Signal_MyECU_SecOC_Rx1_omsg_SecOC_MyECU_Rx_oCAN: start 0, 8 bit, little-endian, i-signal-type=PRIMITIVE, init-value=0, base-type=uint8, compu {identical}, range raw 0..255, transfer-property=PENDING, to MyECU
    signal Signal_MyECU_SecOC_Rx2_omsg_SecOC_MyECU_Rx_oCAN: start 8, 8 bit, little-endian, i-signal-type=PRIMITIVE, init-value=0, base-type=uint8, compu {identical}, range raw 0..255, transfer-property=PENDING, to MyECU
  pdu msg_SecOC_MyECU_Tx_oCAN: length=2, minimum-delay=0, transmission-mode-false-timing=cyclic-timing={time-offset=0, time-period=0.1}, transmission-mode-true-timing=cyclic-timing={time-offset=0, time-period=0.1}, unused-bit-pattern=0
    signal Signal_MyECU_SecOC_Tx1_omsg_SecOC_MyECU_Tx_oCAN: start 0, 8 bit, little-endian, i-signal-type=PRIMITIVE, init-value=0, base-type=uint8, compu {identical}, range raw 0..255, transfer-property=PENDING, to RearECU
    signal Signal_MyECU_SecOC_Tx2_omsg_SecOC_MyECU_Tx_oCAN: start 8, 8 bit, little-endian, i-signal-type=PRIMITIVE, init-value=0, base-type=uint8, compu {identical}, range raw 0..255, transfer-property=PENDING, to RearECU
  pdu msg_SecOC_OtherECU_Rx_oCAN: length=2, minimum-delay=0, transmission-mode-false-timing=cyclic-timing={time-offset=0, time-period=0.1}, transmission-mode-true-timing=cyclic-timing={time-offset=0, time-period=0.1}, unused-bit-pattern=0
    signal Signal_OtherECU_SecOC_Rx1_omsg_SecOC_OtherECU_Rx_oCAN: start 0, 8 bit, little-endian, i-signal-type=PRIMITIVE, init-value=0, base-type=uint8, compu {identical}, range raw 0..255, transfer-property=PENDING, to OtherECU
    signal Signal_OtherECU_SecOC_Rx2_omsg_SecOC_OtherECU_Rx_oCAN: start 8, 8 bit, little-endian, i-signal-type=PRIMITIVE, init-value=0, base-type=uint8, compu {identical}, range raw 0..255, transfer-property=PENDING, to OtherECU
  pdu msg_SecOC_OtherECU_Tx_oCAN: length=2, minimum-delay=0, transmission-mode-false-timing=cyclic-timing={time-offset=0, time-period=0.1}, transmission-mode-true-timing=cyclic-timing={time-offset=0, time-period=0.1}, unused-bit-pattern=0
    signal Signal_OtherECU_SecOC_Tx1_omsg_SecOC_OtherECU_Tx_oCAN: start 0, 8 bit, little-endian, i-signal-type=PRIMITIVE, init-value=0, base-type=uint8, compu {identical}, range raw 0..255, transfer-property=PENDING, to RearECU
    signal Signal_OtherECU_SecOC_Tx2_omsg_SecOC_OtherECU_Tx_oCAN: start 8, 8 bit, little-endian, i-signal-type=PRIMITIVE, init-value=0, base-type=uint8, compu {identical}, range raw 0..255, transfer-property=PENDING, to RearECU
  dcm i pdu msg_diag_Request_MyECU_oCAN: length=8, diag-pdu-type=DIAG-REQUEST
  dcm i pdu msg_diag_Request_MyECU_Slave1_oCAN: length=8, diag-pdu-type=DIAG-REQUEST
  dcm i pdu msg_diag_Request_MyECU_Slave3_oCAN: length=8, diag-pdu-type=DIAG-REQUEST
  dcm i pdu msg_diag_Request_OtherECU_oCAN: length=8, diag-pdu-type=DIAG-REQUEST
  dcm i pdu msg_diag_RequestGlobal_oCAN: length=7, diag-pdu-type=DIAG-REQUEST
  dcm i pdu msg_diag_Response_MyECU_oCAN: length=8, diag-pdu-type=DIAG-RESPONSE
  dcm i pdu msg_diag_Response_MyECU_Slave1_oCAN: length=8, diag-pdu-type=DIAG-RESPONSE
  dcm i pdu msg_diag_Response_MyECU_Slave3_oCAN: length=8, diag-pdu-type=DIAG-RESPONSE
  dcm i pdu msg_diag_Response_OtherECU_oCAN: length=8, diag-pdu-type=DIAG-RESPONSE
package /ISignal
  i signal group SG_RgRx_Prof1C_RxCycle_omsg_RxCycle_E2eProf1C_500_10_oCAN: i-signal=[SigRx_Prof1C_CRC_omsg_RxCycle_E2eProf1C_500_10_oCAN, SigRx_Prof1C_DataId_HiByte_LoNib_omsg_RxCycle_E2eProf1C_500_10_oCAN, SigRx_Prof1C_Sig32Bit_omsg_RxCycle_E2eProf1C_500_10_oCAN, SigRx_Prof1C_Sig3Bit_omsg_RxCycle_E2eProf1C_500_10_oCAN, SigRx_Prof1C_Sig4Bit_omsg_RxCycle_E2eProf1C_500_10_oCAN, SigRx_Prof1C_SQ_omsg_RxCycle_E2eProf1C_500_10_oCAN], system-signal-group=SG_RgRx_Prof1C_RxCycle
  i signal group SG_SgTx_Prof1C_TxCycle_omsg_TxCycle_E2eProf1C_500_30_oCAN: i-signal=[SigTx_Prof1C_CRC_omsg_TxCycle_E2eProf1C_500_30_oCAN, SigTx_Prof1C_DataId_HiByte_LoNib_omsg_TxCycle_E2eProf1C_500_30_oCAN, SigTx_Prof1C_Sig16Bit_omsg_TxCycle_E2eProf1C_500_30_oCAN, SigTx_Prof1C_Sig2Bit_omsg_TxCycle_E2eProf1C_500_30_oCAN, SigTx_Prof1C_Sig4Bit_omsg_TxCycle_E2eProf1C_500_30_oCAN, SigTx_Prof1C_Sig8Bit_omsg_TxCycle_E2eProf1C_500_30_oCAN, SigTx_Prof1C_SQ_omsg_TxCycle_E2eProf1C_500_30_oCAN], system-signal-group=SG_SgTx_Prof1C_TxCycle
package /SecureCommunicationPropsSet
  secure communication props set SecCommPropsSet
    4 x secure communication authentication props, all with auth-info-tx-length=32:
      Authmsg_SecOC_MyECU_Rx_Sc_oCAN
      Authmsg_SecOC_MyECU_Tx_Sc_oCAN
      Authmsg_SecOC_OtherECU_Rx_Sc_oCAN
      Authmsg_SecOC_OtherECU_Tx_Sc_oCAN
    4 x secure communication freshness props, all with freshness-value-length=32, freshness-value-tx-length=16:
      Freshnessmsg_SecOC_MyECU_Rx_Sc_oCAN
      Freshnessmsg_SecOC_MyECU_Tx_Sc_oCAN
      Freshnessmsg_SecOC_OtherECU_Rx_Sc_oCAN
      Freshnessmsg_SecOC_OtherECU_Tx_Sc_oCAN
